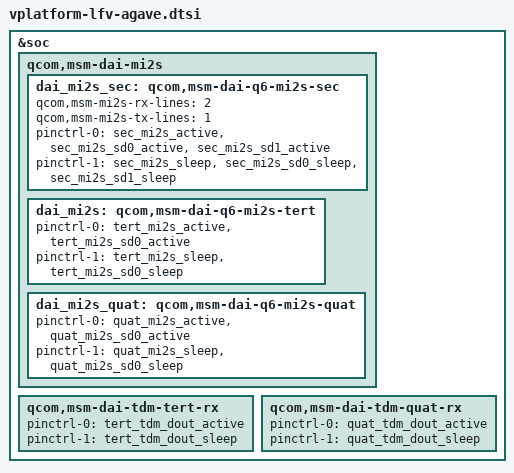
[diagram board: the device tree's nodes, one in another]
/* Copyright (c) 2017, The Linux Foundation. All rights reserved.
 *
 * This program is free software; you can redistribute it and/or modify
 * it under the terms of the GNU General Public License version 2 and
 * only version 2 as published by the Free Software Foundation.
 *
 * This program is distributed in the hope that it will be useful,
 * but WITHOUT ANY WARRANTY; without even the implied warranty of
 * MERCHANTABILITY or FITNESS FOR A PARTICULAR PURPOSE.  See the
 * GNU General Public License for more details.
 */

&soc {
	qcom,msm-dai-mi2s {
		dai_mi2s_sec: qcom,msm-dai-q6-mi2s-sec {
			qcom,msm-mi2s-rx-lines = <2>;
			qcom,msm-mi2s-tx-lines = <1>;
			pinctrl-names = "default", "sleep";
			pinctrl-0 = <&sec_mi2s_active &sec_mi2s_sd0_active
				&sec_mi2s_sd1_active>;
			pinctrl-1 = <&sec_mi2s_sleep &sec_mi2s_sd0_sleep
				&sec_mi2s_sd1_sleep>;
		};

		dai_mi2s: qcom,msm-dai-q6-mi2s-tert {
			pinctrl-names = "default", "sleep";
			pinctrl-0 = <&tert_mi2s_active &tert_mi2s_sd0_active>;
			pinctrl-1 = <&tert_mi2s_sleep &tert_mi2s_sd0_sleep>;
		};

		dai_mi2s_quat: qcom,msm-dai-q6-mi2s-quat {
			pinctrl-names = "default", "sleep";
			pinctrl-0 = <&quat_mi2s_active &quat_mi2s_sd0_active>;
			pinctrl-1 = <&quat_mi2s_sleep &quat_mi2s_sd0_sleep>;
		};
	};

	qcom,msm-dai-tdm-tert-rx {
		pinctrl-names = "default", "sleep";
		pinctrl-0 = <&tert_tdm_dout_active>;
		pinctrl-1 = <&tert_tdm_dout_sleep>;
	};

	qcom,msm-dai-tdm-quat-rx {
		pinctrl-names = "default", "sleep";
		pinctrl-0 = <&quat_tdm_dout_active>;
		pinctrl-1 = <&quat_tdm_dout_sleep>;
	};
};

